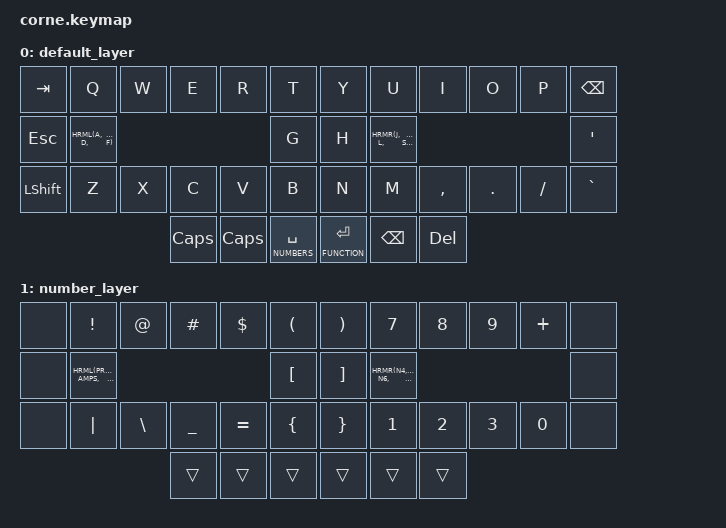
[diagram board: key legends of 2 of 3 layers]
/*
 * Copyright (c) 2020 The ZMK Contributors
 *
 * SPDX-License-Identifier: MIT
 */

#include <behaviors.dtsi>
#include <dt-bindings/zmk/keys.h>
#include <dt-bindings/zmk/bt.h>

#define HRML(k1, k2, k3, k4) &hm LALT k1 &hm LCTRL k2 &hm LGUI k3 &hm LSHFT k4
#define HRMR(k1, k2, k3, k4) &hm RSHFT k1 &hm RGUI k2 &hm RCTRL k3 &hm RALT k4

#define DEFAULT 0
#define NUMBERS 1
#define FUNCTION 2

/ {
        behaviors {
                hm: homerow_mods {
                        compatible = "zmk,behavior-hold-tap";
                        #binding-cells = <2>;
                        tapping-term-ms = <150>;
                        quick-tap-ms = <0>;
                        flavor = "tap-preferred";
                        bindings = <&kp>, <&kp>;
                };
        };
        keymap {
                compatible = "zmk,keymap";

                default_layer {
                        bindings = <
// ╭──────────┬──────────┬──────────┬──────────┬──────────┬──────────╮   ╭──────────┬──────────┬──────────┬──────────┬──────────┬──────────╮
//   TAB        Q          W          E          R          T              Y          U          I          O          P          BSPC
// ├──────────├──────────┼──────────┼──────────┼──────────┼──────────┤   ├──────────├──────────┼──────────┼──────────┼──────────┼──────────┤
//    ESC       A          S          D          F          G              H          J          K          L          ;          '
// ├──────────├──────────┼──────────┼──────────┼──────────┼──────────┤   ├──────────├──────────┼──────────┼──────────┼──────────┼──────────┤
//    LSHIFT    Z          X          C          V          B              N          M          ,          .          /          ` or ~
// ╰──────────┴──────────┴──────────┼──────────┼──────────┼──────────┤   ├──────────├──────────┼──────────┼──────────┴──────────┴──────────╯
//                                   CAPS LOCK  CAPS LOCK  SPACE/num      ENTER/func   BSPC       DEL
//                                  ╰──────────┴──────────┴──────────╯   ╰──────────┴──────────┴──────────╯
     &kp TAB    &kp Q      &kp W      &kp E      &kp R      &kp T          &kp Y      &kp U       &kp I     &kp O      &kp P      &kp BSPC
     &kp ESC    HRML(A,     S,         D,         F)        &kp G          &kp H      HRMR(J,     K,         L,         SEMI)     &kp SQT
     &kp LSHFT  &kp Z      &kp X      &kp C      &kp V      &kp B          &kp N      &kp M      &kp COMMA  &kp DOT    &kp FSLH   &kp GRAVE
                                   &kp CAPS &kp CAPS &lt NUMBERS SPACE  &lt FUNCTION ENTER &kp BSPC &kp DEL
                        >;
                };
                number_layer {
                        bindings = <
// ╭──────────┬──────────┬──────────┬──────────┬──────────┬──────────╮   ╭──────────┬──────────┬──────────┬──────────┬──────────┬──────────╮
//              !          @          #          $          (              )          7          8          9          +              
// ├──────────├──────────┼──────────┼──────────┼──────────┼──────────┤   ├──────────├──────────┼──────────┼──────────┼──────────┼──────────┤
//              %          ^          &          *          [              ]          4          5          6          -         
// ├──────────├──────────┼──────────┼──────────┼──────────┼──────────┤   ├──────────├──────────┼──────────┼──────────┼──────────┼──────────┤
//              |          \          _          =          {              }          1          2          3          0          
// ╰──────────┴──────────┴──────────┼──────────┼──────────┼──────────┤   ├──────────├──────────┼──────────┼──────────┴──────────┴──────────╯
//                                                         [pressed]
//                                  ╰──────────┴──────────┴──────────╯   ╰──────────┴──────────┴──────────╯
     &none      &kp EXCL   &kp AT     &kp HASH   &kp DLLR   &kp LPAR       &kp RPAR   &kp N7     &kp N8     &kp N9     &kp PLUS   &none
     &none      HRML(PRCNT, CARET,     AMPS,      STAR)      &kp LBKT       &kp RBKT   HRMR(N4,   N5,        N6,        MINUS)     &none
     &none      &kp PIPE   &kp BSLH   &kp UNDER  &kp EQUAL  &kp LBRC       &kp RBRC   &kp N1     &kp N2     &kp N3     &kp N0     &none
                                      &trans     &trans     &trans         &trans     &trans     &trans 
                        >;
                };
                function_layer {
                        bindings = <
// ╭──────────┬──────────┬──────────┬──────────┬──────────┬──────────╮   ╭──────────┬──────────┬──────────┬──────────┬──────────┬──────────╮
//   F1         F2         F3         F4         F5         F6             F7         F8         F9         F10        F11        F12
// ├──────────├──────────┼──────────┼──────────┼──────────┼──────────┤   ├──────────├──────────┼──────────┼──────────┼──────────┼──────────┤
//   MUTE       VOL-       VOL+       PREV      PLAY/PAUSE  NEXT           LEFT       DOWN       UP         RIGHT      PG UP      PG DOWN
// ├──────────├──────────┼──────────┼──────────┼──────────┼──────────┤   ├──────────├──────────┼──────────┼──────────┼──────────┼──────────┤
//   BT CLEAR   BT 0       BT 1       BT 2       BT 3       BT 4           HOME       BRIGHT-    BRIGHT+    PRINT      END        INS
// ╰──────────┴──────────┴──────────┼──────────┼──────────┼──────────┤   ├──────────├──────────┼──────────┼──────────┴──────────┴──────────╯
//                                                                        [pressed]
//                                  ╰──────────┴──────────┴──────────╯   ╰──────────┴──────────┴──────────╯
     &kp F1     &kp F2     &kp F3     &kp F4     &kp F5     &kp F6         &kp F7     &kp F8     &kp F9     &kp F10    &kp F11    &kp F12
     &kp C_MUTE &kp C_VOL_DN &kp C_VOL_UP &kp C_PREV &kp C_PP &kp C_NEXT   &kp LEFT   &kp DOWN   &kp UP     &kp RIGHT  &kp PG_UP  &kp PG_DN
     &bt BT_CLR &bt BT_SEL 0 &bt BT_SEL 1 &bt BT_SEL 2 &bt BT_SEL 3 &bt BT_SEL 4  &kp HOME &kp C_BRI_DN &kp C_BRI_UP &kp PSCRN &kp END &kp INS 
                                      &trans     &trans     &trans         &trans     &trans     &trans 
                        >;
                };
        };
};
